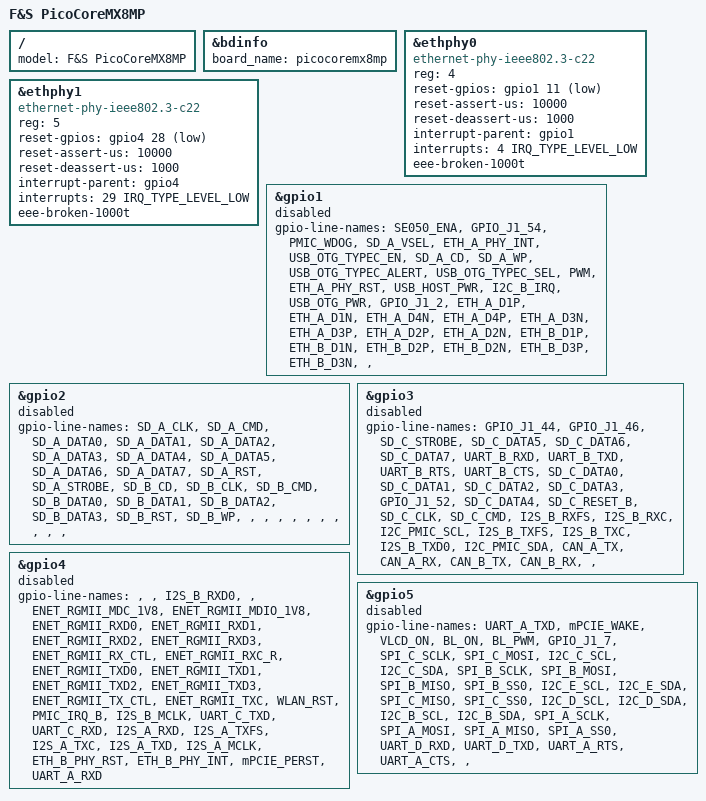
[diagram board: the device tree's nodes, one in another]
/*
 * Copyright (C) 2021 F&S Elektronik Systeme GmbH
 *
 * This program is free software; you can redistribute it and/or modify
 * it under the terms of the GNU General Public License version 2 as
 * published by the Free Software Foundation.
 */

#include "picocoremx8mp-common.dtsi"

/ {
	model = "F&S PicoCoreMX8MP";
};

/* -------------------- BOARD INFO -------------------- */
&bdinfo {
	board_name = "picocoremx8mp";
};

&ethphy0 {
	compatible = "ethernet-phy-ieee802.3-c22";
	reg = <4>;
	reset-gpios = <&gpio1 11 GPIO_ACTIVE_LOW>;
	reset-assert-us = <10000>;
	reset-deassert-us = <1000>;
	interrupt-parent = <&gpio1>;
	interrupts = <4 IRQ_TYPE_LEVEL_LOW>;
	eee-broken-1000t;
};


&ethphy1 {
	compatible = "ethernet-phy-ieee802.3-c22";
	reg = <5>;
	reset-gpios = <&gpio4 28 GPIO_ACTIVE_LOW>;
	reset-assert-us = <10000>;
	reset-deassert-us = <1000>;
	interrupt-parent = <&gpio4>;
	interrupts = <29 IRQ_TYPE_LEVEL_LOW>;
	eee-broken-1000t;
};

/* GPIO declarations */
&gpio1 {
	gpio-line-names =
	/* 0 */   "SE050_ENA", "GPIO_J1_54", "PMIC_WDOG", "SD_A_VSEL",
	/* 4 */   "ETH_A_PHY_INT", "USB_OTG_TYPEC_EN", "SD_A_CD", "SD_A_WP",
	/* 8 */   "USB_OTG_TYPEC_ALERT", "USB_OTG_TYPEC_SEL", "PWM", "ETH_A_PHY_RST",
	/* 12 */  "USB_HOST_PWR", "I2C_B_IRQ", "USB_OTG_PWR", "GPIO_J1_2",
	/* 16 */  "ETH_A_D1P", "ETH_A_D1N", "ETH_A_D4N", "ETH_A_D4P",
	/* 20 */  "ETH_A_D3N", "ETH_A_D3P", "ETH_A_D2P", "ETH_A_D2N",
	/* 24 */  "ETH_B_D1P", "ETH_B_D1N", "ETH_B_D2P", "ETH_B_D2N",
	/* 28 */  "ETH_B_D3P", "ETH_B_D3N", "", "";
	status = "disabled";
};

&gpio2 {
	gpio-line-names =
	/* 0 */   "SD_A_CLK", "SD_A_CMD", "SD_A_DATA0", "SD_A_DATA1",
	/* 4 */   "SD_A_DATA2", "SD_A_DATA3", "SD_A_DATA4", "SD_A_DATA5",
	/* 8 */   "SD_A_DATA6", "SD_A_DATA7", "SD_A_RST", "SD_A_STROBE",
	/* 12 */  "SD_B_CD", "SD_B_CLK", "SD_B_CMD", "SD_B_DATA0",
	/* 16 */  "SD_B_DATA1", "SD_B_DATA2", "SD_B_DATA3", "SD_B_RST",
	/* 20 */  "SD_B_WP", "", "", "",
	/* 24 */  "", "", "", "",
	/* 28 */  "", "", "", "";
	status = "disabled";
};

&gpio3 {
	gpio-line-names =
	/* 0 */   "GPIO_J1_44", "GPIO_J1_46", "SD_C_STROBE", "SD_C_DATA5",
	/* 4 */   "SD_C_DATA6", "SD_C_DATA7", "UART_B_RXD", "UART_B_TXD",
	/* 8 */   "UART_B_RTS", "UART_B_CTS", "SD_C_DATA0", "SD_C_DATA1",
	/* 12 */  "SD_C_DATA2", "SD_C_DATA3", "GPIO_J1_52", "SD_C_DATA4",
	/* 16 */  "SD_C_RESET_B", "SD_C_CLK", "SD_C_CMD", "I2S_B_RXFS",
	/* 20 */  "I2S_B_RXC", "I2C_PMIC_SCL", "I2S_B_TXFS", "I2S_B_TXC",
	/* 24 */  "I2S_B_TXD0", "I2C_PMIC_SDA", "CAN_A_TX", "CAN_A_RX",
	/* 28 */  "CAN_B_TX", "CAN_B_RX", "", "";
	status = "disabled";
};

&gpio4 {
	gpio-line-names =
	/* 0 */   "", "", "I2S_B_RXD0", "",
	/* 4 */   "ENET_RGMII_MDC_1V8", "ENET_RGMII_MDIO_1V8", "ENET_RGMII_RXD0", "ENET_RGMII_RXD1",
	/* 8 */   "ENET_RGMII_RXD2", "ENET_RGMII_RXD3", "ENET_RGMII_RX_CTL", "ENET_RGMII_RXC_R",
	/* 12 */  "ENET_RGMII_TXD0", "ENET_RGMII_TXD1", "ENET_RGMII_TXD2", "ENET_RGMII_TXD3",
	/* 16 */  "ENET_RGMII_TX_CTL", "ENET_RGMII_TXC", "WLAN_RST", "PMIC_IRQ_B",
	/* 20 */  "I2S_B_MCLK", "UART_C_TXD", "UART_C_RXD", "I2S_A_RXD",
	/* 24 */  "I2S_A_TXFS", "I2S_A_TXC", "I2S_A_TXD", "I2S_A_MCLK",
	/* 28 */  "ETH_B_PHY_RST", "ETH_B_PHY_INT", "mPCIE_PERST", "UART_A_RXD";
	status = "disabled";
};

&gpio5 {
	gpio-line-names =
	/* 0 */   "UART_A_TXD", "mPCIE_WAKE", "VLCD_ON", "BL_ON",
	/* 4 */   "BL_PWM", "GPIO_J1_7", "SPI_C_SCLK", "SPI_C_MOSI",
	/* 8 */   "I2C_C_SCL", "I2C_C_SDA", "SPI_B_SCLK", "SPI_B_MOSI",
	/* 12 */  "SPI_B_MISO", "SPI_B_SS0", "I2C_E_SCL", "I2C_E_SDA",
	/* 16 */  "SPI_C_MISO", "SPI_C_SS0", "I2C_D_SCL", "I2C_D_SDA",
	/* 20 */  "I2C_B_SCL", "I2C_B_SDA", "SPI_A_SCLK", "SPI_A_MOSI",
	/* 24 */  "SPI_A_MISO", "SPI_A_SS0", "UART_D_RXD", "UART_D_TXD",
	/* 28 */  "UART_A_RTS", "UART_A_CTS", "", "";
	status = "disabled";
};
